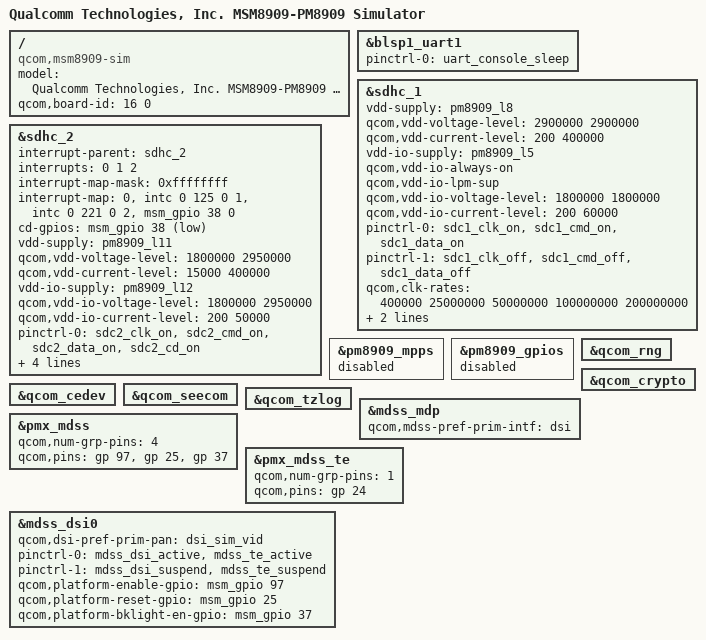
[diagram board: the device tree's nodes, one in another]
/* Copyright (c) 2014, The Linux Foundation. All rights reserved.
 *
 * This program is free software; you can redistribute it and/or modify
 * it under the terms of the GNU General Public License version 2 and
 * only version 2 as published by the Free Software Foundation.
 *
 * This program is distributed in the hope that it will be useful,
 * but WITHOUT ANY WARRANTY; without even the implied warranty of
 * MERCHANTABILITY or FITNESS FOR A PARTICULAR PURPOSE.  See the
 * GNU General Public License for more details.
 */

/dts-v1/;

#include "msm8909.dtsi"
#include "msm8909-pm8909.dtsi"
#include "msm8909-pinctrl.dtsi"

/ {
	model = "Qualcomm Technologies, Inc. MSM8909-PM8909 Simulator";
	compatible = "qcom,msm8909-sim", "qcom,msm8909", "qcom,sim";
	qcom,board-id= <16 0>;
};

&blsp1_uart1 {
	status = "ok";
	pinctrl-names = "default";
	pinctrl-0 = <&uart_console_sleep>;
};

&sdhc_1 {
	vdd-supply = <&pm8909_l8>;
	qcom,vdd-voltage-level = <2900000 2900000>;
	qcom,vdd-current-level = <200 400000>;

	vdd-io-supply = <&pm8909_l5>;
	qcom,vdd-io-always-on;
	qcom,vdd-io-lpm-sup;
	qcom,vdd-io-voltage-level = <1800000 1800000>;
	qcom,vdd-io-current-level = <200 60000>;

	pinctrl-names = "active", "sleep";
	pinctrl-0 = <&sdc1_clk_on &sdc1_cmd_on &sdc1_data_on>;
	pinctrl-1 = <&sdc1_clk_off &sdc1_cmd_off &sdc1_data_off>;

	qcom,clk-rates = <400000 25000000 50000000 100000000 200000000 >;
	qcom,bus-speed-mode = "HS200_1p8v", "DDR_1p8v";
	qcom,nonremovable;

	status = "ok";
};

&sdhc_2 {
	 #address-cells = <0>;
	interrupt-parent = <&sdhc_2>;
	interrupts = <0 1 2>;
	#interrupt-cells = <1>;
	interrupt-map-mask = <0xffffffff>;
	interrupt-map = <0 &intc 0 125 0
			1 &intc 0 221 0
			2 &msm_gpio 38 0>;
	interrupt-names = "hc_irq", "pwr_irq", "status_irq";
	cd-gpios = <&msm_gpio 38 0x1>;

	vdd-supply = <&pm8909_l11>;
	qcom,vdd-voltage-level = <1800000 2950000>;
	qcom,vdd-current-level = <15000 400000>;

	vdd-io-supply = <&pm8909_l12>;
	qcom,vdd-io-voltage-level = <1800000 2950000>;
	qcom,vdd-io-current-level = <200 50000>;

	pinctrl-names = "active", "sleep";
	pinctrl-0 = <&sdc2_clk_on &sdc2_cmd_on &sdc2_data_on &sdc2_cd_on>;
	pinctrl-1 = <&sdc2_clk_off &sdc2_cmd_off &sdc2_data_off &sdc2_cd_off>;

	qcom,clk-rates = <400000 25000000 50000000 100000000 200000000>;

	status = "ok";
};

&pm8909_mpps {
	status = "disabled";
};

&pm8909_gpios {
	status = "disabled";
};

&qcom_rng {
	status = "okay";
};

&qcom_crypto {
	status = "okay";
};

&qcom_cedev {
	status = "okay";
};

&qcom_seecom {
	status = "okay";
};

&qcom_tzlog {
	status = "okay";
};

&mdss_mdp {
	qcom,mdss-pref-prim-intf = "dsi";
};

&pmx_mdss {
	qcom,num-grp-pins = <4>;
	qcom,pins = <&gp 97>, <&gp 25>, <&gp 37>;
};

&pmx_mdss_te {
	qcom,num-grp-pins = <1>;
	qcom,pins = <&gp 24>;
};

&mdss_dsi0 {
	qcom,dsi-pref-prim-pan = <&dsi_sim_vid>;
	pinctrl-names = "mdss_default", "mdss_sleep";
	pinctrl-0 = <&mdss_dsi_active &mdss_te_active>;
	pinctrl-1 = <&mdss_dsi_suspend &mdss_te_suspend>;

	qcom,platform-enable-gpio = <&msm_gpio 97 0>;
	qcom,platform-reset-gpio = <&msm_gpio 25 0>;
	qcom,platform-bklight-en-gpio = <&msm_gpio 37 0>;
};
